# 3066H register map
File version: 1.0
Registers are 32-bit, access per field, reset 0x0 unless marked. A register's access mark holds for its fields unless they carry their own. Offsets are from the block's base; [hi:lo] are bit positions; {n}, {i} and the like mark numbered series; 'fields as' and 'values as' point back to an identical list.

## CRG — CRG peripheral interface
Base 0x10000000
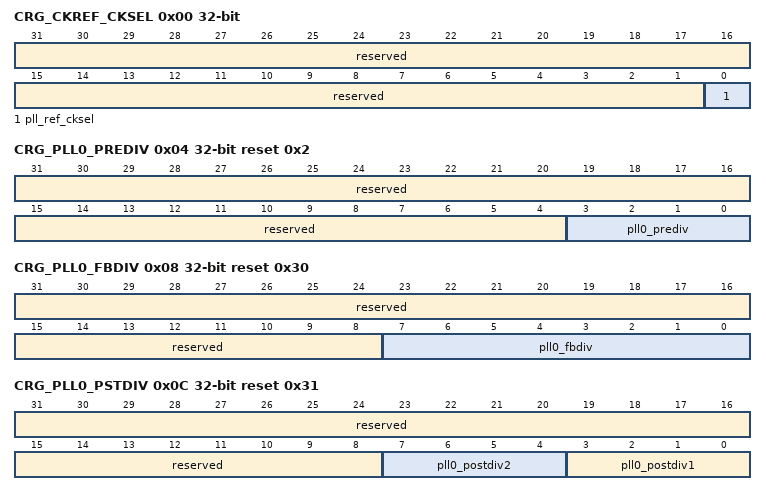
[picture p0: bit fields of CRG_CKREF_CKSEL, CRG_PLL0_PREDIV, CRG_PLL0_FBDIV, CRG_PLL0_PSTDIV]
0x00 CRG_CKREF_CKSEL access not given — CRG_CKREF_CKSEL为PLL参考钟选择寄存器。
  [31:1] reserved ro — 保留。
  [0] pll_ref_cksel — pll_ref_cksel信号。 0：选择HOSC； 1：选择晶振时钟。
0x04 CRG_PLL0_PREDIV access not given reset 0x2 — CRG_PLL0_PREDIV为自研PLL0寄存器0。
  [31:4] reserved ro — 保留。
  [3:0] pll0_prediv — pll0_prediv信号。 0x0：div1； 0x1：div2； 0x2：div3； 0x3：div4； 0x4：div5； 0x5：div6； 0x6：div7； 0x7：div8； 其他配置值：不使用。
0x08 CRG_PLL0_FBDIV access not given reset 0x30 — CRG_PLL0_FBDIV为自研PLL0寄存器1。
  [31:8] reserved ro — 保留。
  [7:0] pll0_fbdiv — pll0环路分频比。 0x00 ~ 0x06：div6； 0x07 ~ 0x7F：pll0_fbdiv； 其他配置值：不使用。 1MSB忽略。
0x0C CRG_PLL0_PSTDIV access not given reset 0x31 — CRG_PLL0_PSTDIV为自研PLL0寄存器2。
  [31:8] reserved ro — 保留。
  [7:4] pll0_postdiv2 — pll0_postdiv2信号。 0x0：÷1； 0x1：÷2； 0x2：÷3； 0x3：÷4； 0x4：÷5； 0x5：÷6； 0x6：÷7； 0x7：÷8； 其他配置值：不使用。
  [3:0] pll0_postdiv1 — pll0_postdiv1信号。 0x0：÷1； 0x1：÷2； 0x2：÷3； 0x3：÷4； 0x4：÷5； 0x5：÷6； 0x6：÷7； 0x7：÷8； 其他配置值：不使用。
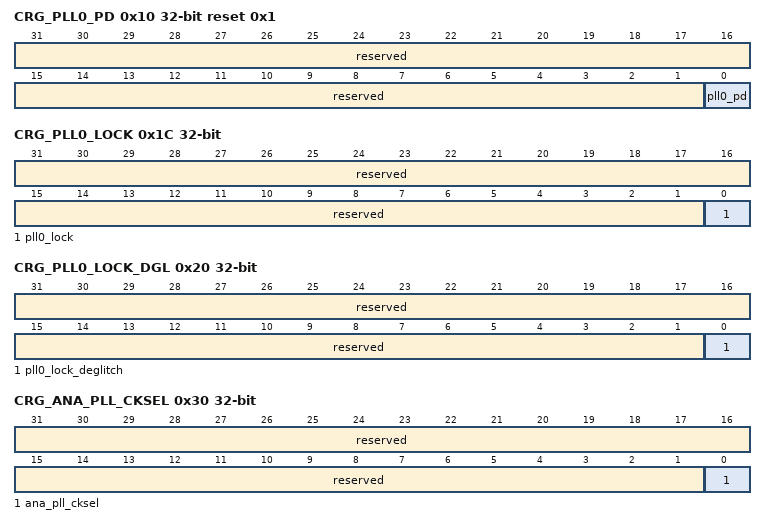
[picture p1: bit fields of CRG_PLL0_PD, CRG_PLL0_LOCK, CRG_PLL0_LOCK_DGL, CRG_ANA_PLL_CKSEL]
0x10 CRG_PLL0_PD access not given reset 0x1 — CRG_PLL0_PD为自研PLL0寄存器3。
  [31:1] reserved ro — 保留。
  [0] pll0_pd — pll0掉电使能（power down）。 0：pll0使能； 1：pll0掉电（power down）。
0x1C CRG_PLL0_LOCK ro — CRG_PLL0_LOCK为PLL0输出lock信息寄存器。
  [31:1] reserved — 保留。
  [0] pll0_lock — pll0 lock信号。 0：unlock； 1：lock。
0x20 CRG_PLL0_LOCK_DGL ro — CRG_PLL0_LOCK_DGL为PLL0输出lock去毛刺信号寄存器。
  [31:1] reserved — 保留。
  [0] pll0_lock_deglitch — pll0 lock硬件虑毛刺之后信号。 0：unlock； 1：lock。
0x30 CRG_ANA_PLL_CKSEL access not given — CRG_ANA_PLL_CKSEL为100MHz模拟时钟源选择寄存器。
  [31:1] reserved ro — 保留。
  [0] ana_pll_cksel — ana_pll_cksel信号。 0：FOUT_ANA（100MHz）时钟来自于PLL0； 1：FOUT_ANA（100MHz）时钟来自于PLL1。
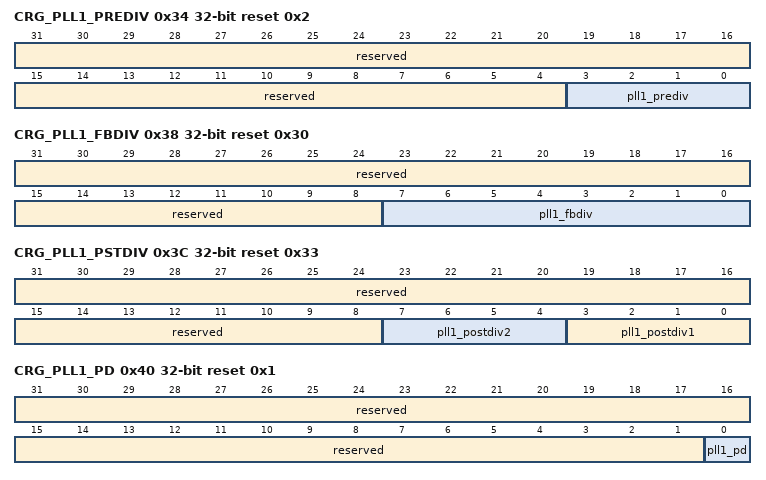
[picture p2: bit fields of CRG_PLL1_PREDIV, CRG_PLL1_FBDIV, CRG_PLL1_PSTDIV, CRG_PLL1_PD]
0x34 CRG_PLL1_PREDIV access not given reset 0x2 — CRG_PLL1_PREDIV为自研PLL1寄存器0。
  [31:4] reserved ro — 保留。
  [3:0] pll1_prediv — pll1_prediv信号。 0x0：div1； 0x1：div2； 0x2：div3； 0x3：div4； 0x4：div5； 0x5：div6； 0x6：div7； 0x7：div8； 其他配置值：不使用。
0x38 CRG_PLL1_FBDIV access not given reset 0x30 — CRG_PLL1_FBDIV为自研PLL1寄存器1。
  [31:8] reserved ro — 保留。
  [7:0] pll1_fbdiv — pll1环路分频比。 0x00~0x06：div6； 0x07~0x7F：pll1_FBDIV； 其他配置值：不使用。 1MSB忽略。
0x3C CRG_PLL1_PSTDIV access not given reset 0x33 — CRG_PLL1_PSTDIV为自研PLL1寄存器2。
  [31:8] reserved ro — 保留。
  [7:4] pll1_postdiv2 — pll1_postdiv2信号。 0x0：÷1； 0x1：÷2； 0x2：÷3； 0x3：÷4； 0x4：÷5； 0x5：÷6； 0x6：÷7； 0x7：÷8； 其他配置值：不使用。
  [3:0] pll1_postdiv1 — pll1_postdiv1信号。 0x0：÷1； 0x1：÷2； 0x2：÷3； 0x3：÷4； 0x4：÷5； 0x5：÷6； 0x6：÷7； 0x7：÷8； 其他配置值：不使用。
0x40 CRG_PLL1_PD access not given reset 0x1 — CRG_PLL1_PD为自研PLL1寄存器3。
  [31:1] reserved ro — 保留。
  [0] pll1_pd — pll1掉电使能（power down）。 0：pll1使能； 1：pll1掉电（power down）。
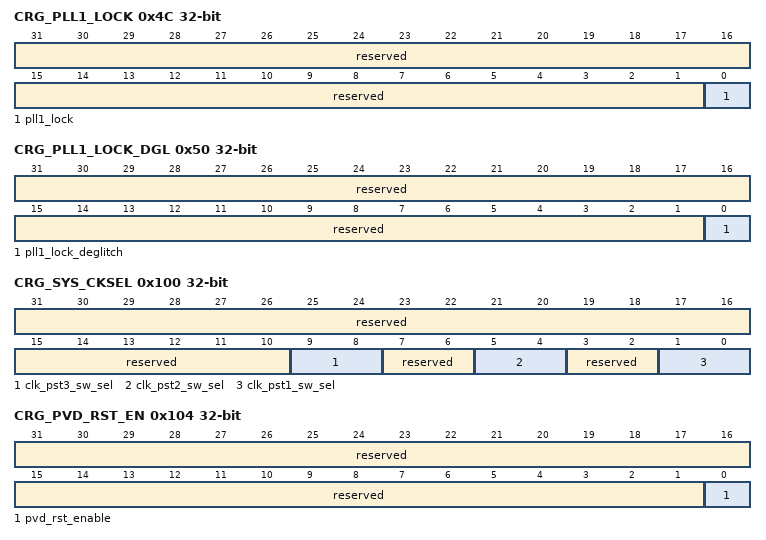
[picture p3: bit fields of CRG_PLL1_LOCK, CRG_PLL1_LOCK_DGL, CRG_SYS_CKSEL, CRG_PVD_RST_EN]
0x4C CRG_PLL1_LOCK ro — CRG_PLL1_LOCK为PLL1输出lock信息寄存器。
  [31:1] reserved — 保留。
  [0] pll1_lock — pll1 lock信号。 0：unlock； 1：lock。
0x50 CRG_PLL1_LOCK_DGL ro — CRG_PLL1_LOCK_DGL为PLL1输出lock去毛刺信号寄存器。
  [31:1] reserved — 保留。
  [0] pll1_lock_deglitch — pll1 lock硬件虑毛刺之后信号。 0：unlock； 1：lock。
0x100 CRG_SYS_CKSEL access not given — CRG_SYS_CKSEL为系统时钟控制寄存器。
  [31:10] reserved ro — 保留。
  [9:8] clk_pst3_sw_sel — clk_pst3_sw_sel信号。 00：选择HOSC； 01：选择晶振时钟； 10：选择PLL输出时钟； 其他：保留。
  [7:6] reserved ro — 保留。
  [5:4] clk_pst2_sw_sel — clk_pst2_sw_sel信号。 00：选择HOSC； 01：选择晶振时钟； 10：选择PLL输出时钟； 其他：保留。
  [3:2] reserved ro — 保留。
  [1:0] clk_pst1_sw_sel — hclk_sw_sel信号。 00：选择HOSC； 01：选择晶振时钟； 10：选择PLL输出时钟； 其他：保留。
0x104 CRG_PVD_RST_EN — CRG_PVD_RST_EN为PVD复位控制寄存器。
  [31:1] reserved ro — 保留。
  [0] pvd_rst_enable rw — pvd_rst使能寄存器。 0：不使能； 1：使能。
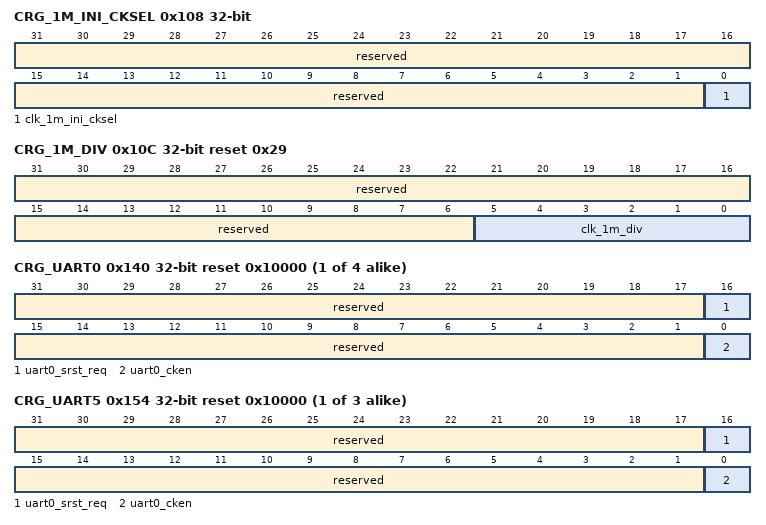
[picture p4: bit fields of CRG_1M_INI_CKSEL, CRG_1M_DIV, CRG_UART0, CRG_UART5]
0x108 CRG_1M_INI_CKSEL — CRG_1M_INI_CKSEL为CLK_1M时钟源头选择控制寄存器。
  [31:1] reserved ro — 保留。
  [0] clk_1m_ini_cksel rw — clk_1m_ini_cksel信号。 0：选择HOSC，default； 1：选择外部晶振时钟。 默认使用HOSC时钟。
0x10C CRG_1M_DIV reset 0x29 — CRG_1M_DIV为CLK_1M时钟分频控制寄存器。
  [31:6] reserved ro — 保留。
  [5:0] clk_1m_div rw — clk_1m分频参数。 输出时钟频率为输入时钟频率/（clk_1m_tick_div + 1）。 默认42分频，配0x29。
{0x140+4i} CRG_UART{i} reset 0x10000 (i=0..3) — CRG_UART{i}为UART{i}时钟及软复位控制寄存器。
  [31:17] reserved ro — 保留。
  [16] uart{i}_srst_req rw — UART{i}软复位请求。 0：不复位； 1：复位。
  [15:1] reserved ro — 保留。
  [0] uart{i}_cken rw — UART{i}时钟门控。 0：关断； 1：打开。
0x150 CRG_UART4 reset 0x10000 — CRG_UART4为UART4时钟及软复位控制寄存器。
  [16] uart4_srst_req rw — UART4软复位请求。 0：不复位； 1：复位。
  [31:14] reserved ro — 保留。
  [15:1] reserved ro — 保留。
  [0] uart4_cken rw — UART4时钟门控。 0：关断； 1：打开。
{0x140+4i} CRG_UART{i} reset 0x10000 (i=5..7) — CRG_UART{i}为UART{i}时钟及软复位控制寄存器。
  fields as CRG_UART0
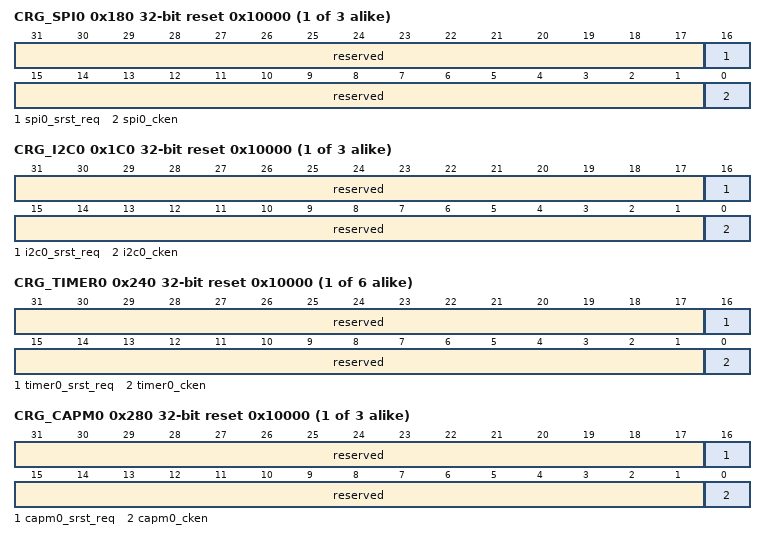
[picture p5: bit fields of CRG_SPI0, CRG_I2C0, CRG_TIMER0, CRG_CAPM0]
{0x180+4i} CRG_SPI{i} reset 0x10000 (i=0..2) — CRG_SPI{i}为SPI{i}时钟及软复位控制寄存器。
  [31:17] reserved ro — 保留。
  [16] spi{i}_srst_req rw — SPI{i}软复位请求。 0：不复位； 1：复位。
  [15:1] reserved ro — 保留。
  [0] spi{i}_cken rw — SPI{i}时钟门控。 0：关断； 1：打开。
{0x1C0+4i} CRG_I2C{i} reset 0x10000 (i=0..2) — CRG_I2C{i}为I2C时钟及软复位控制寄存器{i}。
  [31:17] reserved ro — 保留。
  [16] i2c{i}_srst_req rw — I2C{i}软复位请求。 0：不复位； 1：复位。
  [15:1] reserved ro — 保留。
  [0] i2c{i}_cken rw — I2C{i}时钟门控。 0：关断； 1：打开。
{0x240+4i} CRG_TIMER{i} reset 0x10000 (i=0..5) — CRG_TIMER{i}为Timer{i}时钟及软复位控制寄存器。
  [31:17] reserved ro — 保留。
  [16] timer{i}_srst_req rw — TIMER{i}软复位请求。 0：不复位； 1：复位。
  [15:1] reserved ro — 保留。
  [0] timer{i}_cken rw — TIMER{i}时钟门控。 0：关断； 1：打开。
{0x280+4i} CRG_CAPM{i} reset 0x10000 (i=0..2) — CRG_CAPM{i}为CAPM{i}时钟及软复位控制寄存器。
  [31:17] reserved ro — 保留。
  [16] capm{i}_srst_req rw — CAPM{i}软复位请求。 0：不复位； 1：复位。
  [15:1] reserved ro — 保留。
  [0] capm{i}_cken rw — CAPM{i}时钟门控。 0：关断； 1：打开。
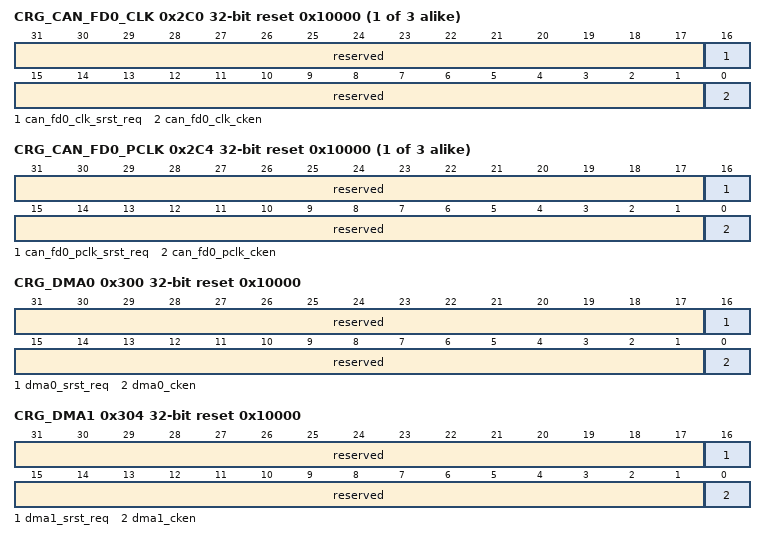
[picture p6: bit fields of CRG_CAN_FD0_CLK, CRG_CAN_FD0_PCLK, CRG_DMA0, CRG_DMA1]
{0x2C0+8i} CRG_CAN_FD{i}_CLK reset 0x10000 (i=0..2) — CRG_CAN_FD{i}_CLK为CAN_FD{i}工作时钟及软复位控制寄存器。
  [31:17] reserved ro — 保留。
  [16] can_fd{i}_clk_srst_req rw — clk_can_fd{i}软复位请求。 0：不复位； 1：复位。
  [15:1] reserved ro — 保留。
  [0] can_fd{i}_clk_cken rw — clk_can_fd{i}时钟门控。 0：关断； 1：打开。
{0x2C4+8i} CRG_CAN_FD{i}_PCLK reset 0x10000 (i=0..2) — CRG_CAN_FD{i}_PCLK为CAN_FD{i}总线时钟及软复位控制寄存器。
  [31:17] reserved ro — 保留。
  [16] can_fd{i}_pclk_srst_req rw — pclk_can_fd{i}软复位请求。 0：不复位； 1：复位。
  [15:1] reserved ro — 保留。
  [0] can_fd{i}_pclk_cken rw — pclk_can_fd{i}时钟门控。 0：关断； 1：打开。
0x300 CRG_DMA0 reset 0x10000 — CRG_DMA0为DMA0时钟及软复位控制寄存器。
  [31:17] reserved ro — 保留。
  [16] dma0_srst_req rw — DMA0软复位请求。 0：不复位； 1：复位。
  [15:1] reserved ro — 保留。
  [0] dma0_cken rw — DMA0时钟门控。 0：关断； 1：打开。
0x304 CRG_DMA1 reset 0x10000 — CRG_DMA1为DMA1时钟及软复位控制寄存器。
  [31:17] reserved ro — 保留。
  [16] dma1_srst_req rw — DMA1软复位请求。 0：不复位； 1：复位。
  [15:1] reserved ro — 保留。
  [0] dma1_cken rw — DMA1时钟门控。 0：关断； 1：打开。
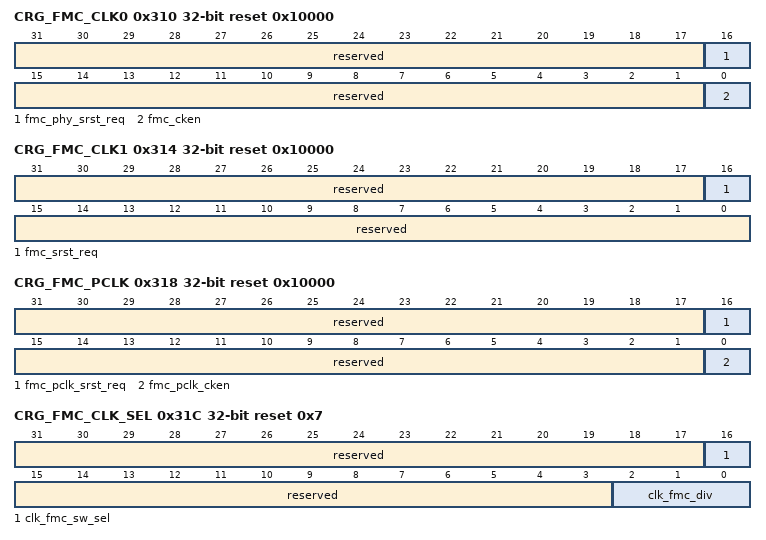
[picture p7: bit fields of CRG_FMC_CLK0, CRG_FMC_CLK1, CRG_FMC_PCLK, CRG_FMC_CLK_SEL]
0x310 CRG_FMC_CLK0 reset 0x10000 — CRG_FMC_CLK0为FMC时钟及软复位控制寄存器0。
  [31:17] reserved ro — 保留。
  [16] fmc_phy_srst_req rw — clk_fmc_phy软复位请求。 0：不复位； 1：复位。
  [15:1] reserved ro — 保留。
  [0] fmc_cken rw — clk_fmc时钟门控。 0：关断； 1：打开。
0x314 CRG_FMC_CLK1 reset 0x10000 — CRG_FMC_CLK1为FMC时钟及软复位控制寄存器1。
  [31:17] reserved ro — 保留。
  [16] fmc_srst_req rw — clk_fmc软复位请求。 0：不复位； 1：复位。
  [15:0] reserved ro — 保留。
0x318 CRG_FMC_PCLK reset 0x10000 — CRG_FMC_PCLK为FMC_PCLK时钟及软复位控制寄存器。
  [31:17] reserved ro — 保留。
  [16] fmc_pclk_srst_req rw — pclk_fmc软复位请求。 0：不复位； 1：复位。
  [15:1] reserved ro — 保留。
  [0] fmc_pclk_cken rw — pclk_fmc时钟门控。 0：关断； 1：打开。
0x31C CRG_FMC_CLK_SEL reset 0x7 — CRG_FMC_CLK_SEL为FMC_CLK_SEL时钟选择控制寄存器。
  [31:17] reserved ro — 保留。
  [16] clk_fmc_sw_sel rw — clk_fmc_sw_sel信号。 0：选择VCO时钟（clk_fmc_div + 1）分频； 1：选择HOSC时钟。
  [15:3] reserved ro — 保留。
  [2:0] clk_fmc_div rw — fmc_phy时钟分频参数。 输出时钟频率为输入时钟频率/（clk_fmc_div + 1）。 不分频，配0。
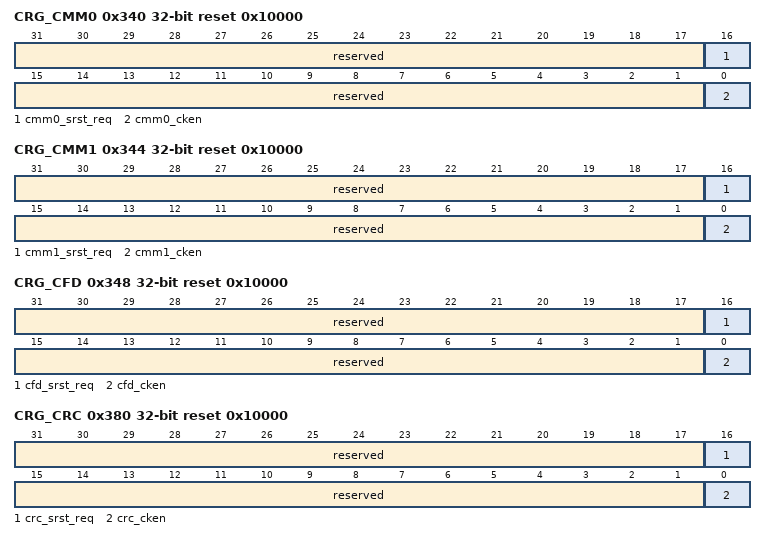
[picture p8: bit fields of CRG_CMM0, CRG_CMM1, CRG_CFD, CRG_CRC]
0x340 CRG_CMM0 reset 0x10000 — CRG_CMM0为CMM0时钟及软复位控制寄存器。
  [31:17] reserved ro — 保留。
  [16] cmm0_srst_req rw — CMM0软复位请求。 0：不复位； 1：复位。
  [15:1] reserved ro — 保留。
  [0] cmm0_cken rw — CMM0时钟门控。 0：关断； 1：打开。
0x344 CRG_CMM1 reset 0x10000 — CRG_CMM1为CMM1时钟及软复位控制寄存器。
  [31:17] reserved ro — 保留。
  [16] cmm1_srst_req rw — CMM1软复位请求。 0：不复位； 1：复位。
  [15:1] reserved ro — 保留。
  [0] cmm1_cken rw — CMM1时钟门控。 0：关断； 1：打开。
0x348 CRG_CFD reset 0x10000 — CRG_CFD为CFD时钟及软复位控制寄存器。
  [31:17] reserved ro — 保留。
  [16] cfd_srst_req rw — CFD软复位请求。 0：不复位； 1：复位。
  [15:1] reserved ro — 保留。
  [0] cfd_cken rw — CFD时钟门控。 0：关断； 1：打开。
0x380 CRG_CRC reset 0x10000 — CRG_CRC为CRC时钟及软复位控制寄存器。
  [31:17] reserved ro — 保留。
  [16] crc_srst_req rw — CRC软复位请求。 0：不复位； 1：复位。
  [15:1] reserved ro — 保留。
  [0] crc_cken rw — CRC时钟门控。 0：关断； 1：打开。
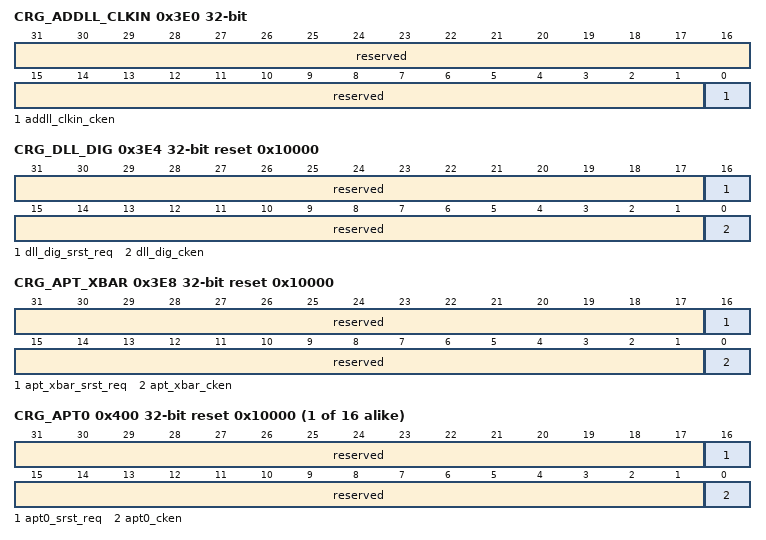
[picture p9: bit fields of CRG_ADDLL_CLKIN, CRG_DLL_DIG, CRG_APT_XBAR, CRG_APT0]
0x3E0 CRG_ADDLL_CLKIN — CRG_ADDLL_CLKIN为ADDLL_CLKIN时钟及软复位控制寄存器。
  [31:1] reserved ro — 保留。
  [0] addll_clkin_cken rw — addll_clkin时钟门控。 0：关断； 1：打开。
0x3E4 CRG_DLL_DIG reset 0x10000 — CRG_DLL_DIG为DLL_DIG时钟及软复位控制寄存器。
  [31:17] reserved ro — 保留。
  [16] dll_dig_srst_req rw — dll_dig软复位请求。 0：不复位； 1：复位。
  [15:1] reserved ro — 保留。
  [0] dll_dig_cken rw — dll_dig时钟门控。 0：关断； 1：打开。
0x3E8 CRG_APT_XBAR reset 0x10000 — CRG_APT_XBAR为APT_XBAR时钟及软复位控制寄存器。
  [31:17] reserved ro — 保留。
  [16] apt_xbar_srst_req rw — apt_xbar软复位请求。 0：不复位； 1：复位。
  [15:1] reserved ro — 保留。
  [0] apt_xbar_cken rw — apt_xbar时钟门控。 0：关断； 1：打开。
{0x400+4i} CRG_APT{i} reset 0x10000 (i=0..15) — CRG_APT{i}为APT{i}时钟及软复位控制寄存器。
  [31:17] reserved ro — 保留。
  [16] apt{i}_srst_req rw — APT{i}软复位请求。 0：不复位； 1：复位。
  [15:1] reserved ro — 保留。
  [0] apt{i}_cken rw — APT{i}时钟门控。 0：关断； 1：打开。
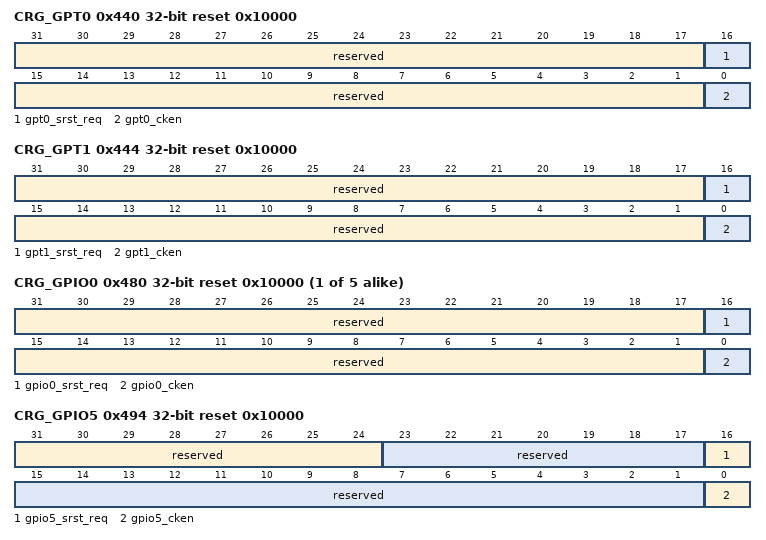
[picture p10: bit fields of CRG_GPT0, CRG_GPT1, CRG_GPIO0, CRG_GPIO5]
0x440 CRG_GPT0 reset 0x10000 — CRG_GPT0为GPT0时钟及软复位控制寄存器。
  [31:17] reserved ro — 保留。
  [16] gpt0_srst_req rw — GPT0软复位请求。 0：不复位； 1：复位。
  [15:1] reserved ro — 保留。
  [0] gpt0_cken rw — GPT0时钟门控。 0：关断； 1：打开。
0x444 CRG_GPT1 reset 0x10000 — CRG_GPT1为GPT1时钟及软复位控制寄存器。
  [31:17] reserved ro — 保留。
  [16] gpt1_srst_req rw — GPT1软复位请求。 0：不复位； 1：复位。
  [15:1] reserved ro — 保留。
  [0] gpt1_cken rw — GPT1时钟门控。 0：关断； 1：打开。
{0x480+4i} CRG_GPIO{i} reset 0x10000 (i=0..4) — CRG_GPIO{i}为GPIO{i}时钟及软复位控制寄存器。
  [31:17] reserved ro — 保留。
  [16] gpio{i}_srst_req rw — GPIO{i}软复位请求。 0：不复位； 1：复位。
  [15:1] reserved ro — 保留。
  [0] gpio{i}_cken rw — GPIO{i}时钟门控。 0：关断； 1：打开。
0x494 CRG_GPIO5 reset 0x10000 — CRG_GPIO5为GPIO5时钟及软复位控制寄存器。
  [31:24] reserved ro — 保留。
  [23:17] reserved ro — 保留。
  [16] gpio5_srst_req rw — GPIO5软复位请求。 0：不复位； 1：复位。
  [15:1] reserved ro — 保留。
  [0] gpio5_cken rw — GPIO5时钟门控。 0：关断； 1：打开。
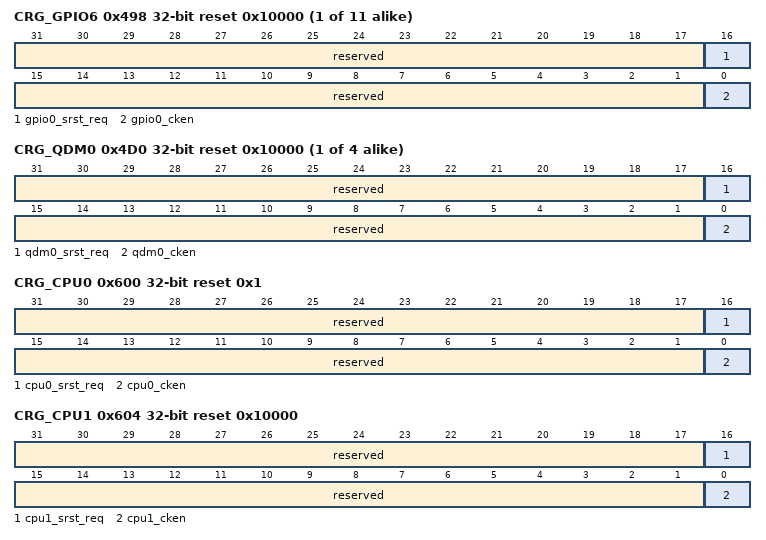
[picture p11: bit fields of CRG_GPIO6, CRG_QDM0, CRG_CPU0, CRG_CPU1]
{0x480+4i} CRG_GPIO{i} reset 0x10000 (i=6..16) — CRG_GPIO{i}为GPIO{i}时钟及软复位控制寄存器。
  fields as CRG_GPIO0
{0x4D0+4i} CRG_QDM{i} reset 0x10000 (i=0..3) — CRG_QDM{i}为QDM{i}时钟及软复位控制寄存器。
  [31:17] reserved ro — 保留。
  [16] qdm{i}_srst_req rw — QDM{i}软复位请求。 0：不复位； 1：复位。
  [15:1] reserved ro — 保留。
  [0] qdm{i}_cken rw — QDM{i}时钟门控。 0：关断； 1：打开。
0x600 CRG_CPU0 reset 0x1 — CRG_CPU0为CPU0时钟及软复位控制寄存器。
  [31:17] reserved ro — 保留。
  [16] cpu0_srst_req rw — CPU0软复位请求。 0：不复位； 1：复位。
  [15:1] reserved ro — 保留。
  [0] cpu0_cken rw — CPU0时钟门控。 0：关断； 1：打开。
0x604 CRG_CPU1 reset 0x10000 — CRG_CPU1为CPU1时钟及软复位控制寄存器。
  [31:17] reserved ro — 保留。
  [16] cpu1_srst_req rw — CPU1软复位请求。 0：不复位； 1：复位。
  [15:1] reserved ro — 保留。
  [0] cpu1_cken rw — CPU1时钟门控。 0：关断； 1：打开。
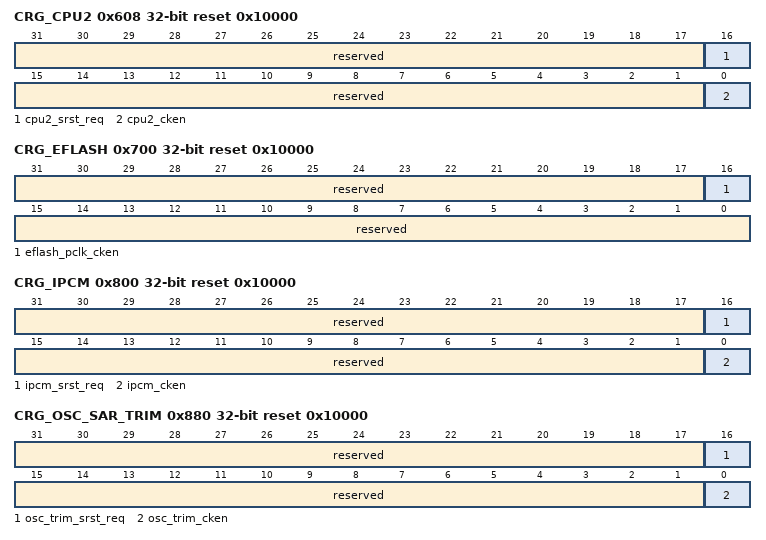
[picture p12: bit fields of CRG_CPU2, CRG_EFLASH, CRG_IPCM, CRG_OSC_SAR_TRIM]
0x608 CRG_CPU2 reset 0x10000 — CRG_CPU2为CPU2时钟及软复位控制寄存器。
  [31:17] reserved ro — 保留。
  [16] cpu2_srst_req rw — CPU2软复位请求。 0：不复位； 1：复位。
  [15:1] reserved ro — 保留。
  [0] cpu2_cken rw — CPU2时钟门控。 0：关断； 1：打开。
0x700 CRG_EFLASH access not given reset 0x10000 — CRG_EFLASH为eFLASH时钟控制寄存器。
  [31:17] reserved ro — 保留。
  [16] eflash_pclk_cken — eflash_pclk_cken时钟门控。 0：关断； 1：打开。
  [15:0] reserved ro — 保留。
0x800 CRG_IPCM reset 0x10000 — CRG_IPCM为IPCM时钟及软复位控制寄存器。
  [31:17] reserved ro — 保留。
  [16] ipcm_srst_req rw — IPCM软复位请求。 0：不复位； 1：复位。
  [15:1] reserved ro — 保留。
  [0] ipcm_cken rw — IPCM时钟门控。 0：关断； 1：打开。
0x880 CRG_OSC_SAR_TRIM reset 0x10000 — CRG_OSC_SAR_TRIM为OSC_SAR_TRIM时钟及软复位控制寄存器。
  [31:17] reserved ro — 保留。
  [16] osc_trim_srst_req rw — osc_trim软复位请求。 0：不复位； 1：复位。
  [15:1] reserved ro — 保留。
  [0] osc_trim_cken rw — osc_trim时钟门控。 0：关断； 1：打开。
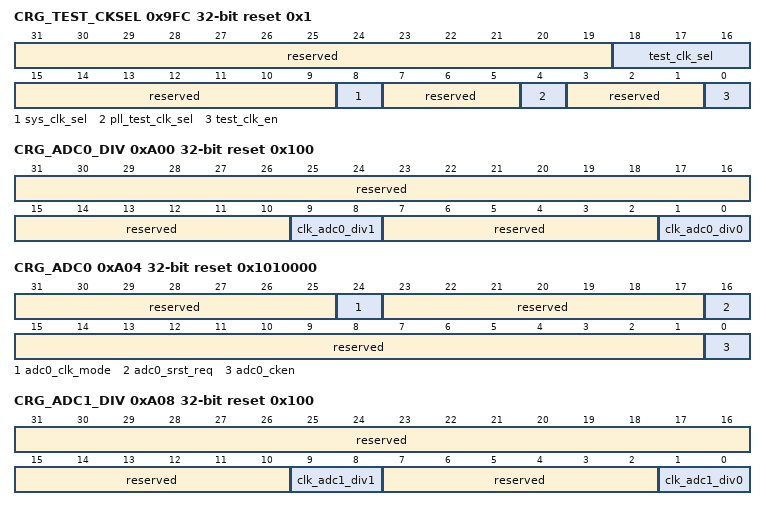
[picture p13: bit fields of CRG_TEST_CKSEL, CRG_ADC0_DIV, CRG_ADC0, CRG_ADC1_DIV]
0x9FC CRG_TEST_CKSEL reset 0x1 — CRG_TEST_CKSEL为TEST时钟选择控制寄存器。
  [31:19] reserved ro — 保留。
  [18:16] test_clk_sel rw — TEST_CLK时钟选择。 000：pll_test时钟； 001：clk_hosc； 010：clk_losc； 011：clk_tcxo； 100：clk_bg_chopper； 101：clk_adc/4； 110：sys_clk/6； 111：clk_hosc_div。
  [15:9] reserved ro — 保留。
  [8] sys_clk_sel rw — sys_clk时钟选择。 0：clk_hs时钟； 1：clk_ls时钟。
  [7:5] reserved ro — 保留。
  [4] pll_test_clk_sel rw — pll_test时钟选择。 0：pll0_test时钟； 1：pll1_test时钟。
  [3:1] reserved ro — 保留。
  [0] test_clk_en rw — test_clk_en。 0：不使能； 1：使能。
0xA00 CRG_ADC0_DIV reset 0x100 — CRG_ADC0_DIV为ADC0分频时钟配置寄存器。
  [31:10] reserved ro — 保留。
  [9:8] clk_adc0_div1 rw — clk_adc0 I1路时钟分频参数 输出时钟频率为输入时钟频率/（clk_adc_div + 1）。 默认二分频，配1。
  [7:2] reserved ro — 保留。
  [1:0] clk_adc0_div0 rw — clk_adc0 I0路时钟分频参数 输出时钟频率为输入时钟频率/（clk_adc_div + 1）。 默认不分频，配0。
0xA04 CRG_ADC0 reset 0x1010000 — CRG_ADC0为ADC0时钟及软复位控制寄存器
  [31:25] reserved ro — 保留。
  [24] adc0_clk_mode rw — clk_adc0选择信号。 0：选择I0路，PLL FOUTPOSTDIV2出来100M时钟，default； 1：选择I1路，主频时钟经过分频后的时钟。
  [23:17] reserved ro — 保留。
  [16] adc0_srst_req rw — ADC0软复位请求。 0：不复位； 1：复位。
  [15:1] reserved ro — 保留。
  [0] adc0_cken rw — ADC0时钟门控。 0：关断； 1：打开。
0xA08 CRG_ADC1_DIV reset 0x100 — CRG_ADC1_DIV为ADC1分频时钟配置寄存器
  [31:10] reserved ro — 保留。
  [9:8] clk_adc1_div1 rw — clk_adc1 I1路时钟分频参数。 输出时钟频率为输入时钟频率/（clk_adc_div + 1）。 默认二分频，配1。
  [7:2] reserved ro — 保留。
  [1:0] clk_adc1_div0 rw — clk_adc1 I0路时钟分频参数。 输出时钟频率为输入时钟频率/（clk_adc_div + 1）。 默认不分频，配0。
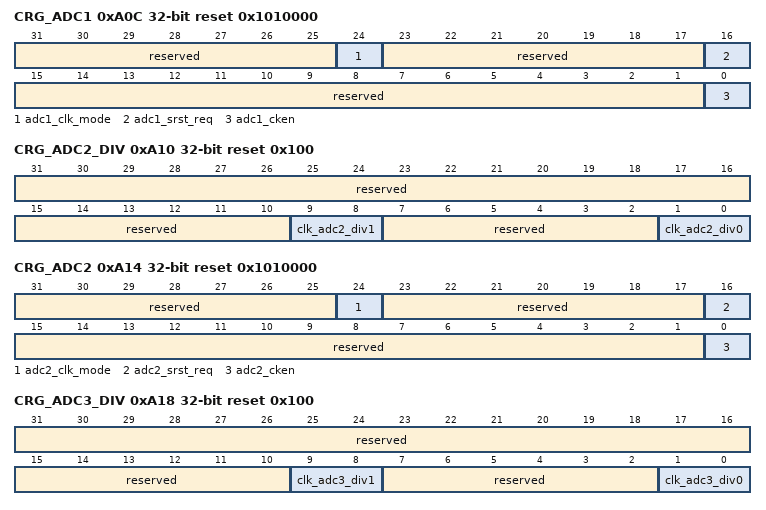
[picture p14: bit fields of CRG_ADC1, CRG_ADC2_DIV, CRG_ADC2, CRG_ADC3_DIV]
0xA0C CRG_ADC1 reset 0x1010000 — CRG_ADC1为ADC1时钟及软复位控制寄存器
  [31:25] reserved ro — 保留。
  [24] adc1_clk_mode rw — clk_adc1选择信号。 0：选择I0路，PLL FOUTPOSTDIV2出来100M时钟，default； 1：选择I1路，主频时钟经过分频后的时钟。
  [23:17] reserved ro — 保留。
  [16] adc1_srst_req rw — ADC1软复位请求。 0：不复位； 1：复位。
  [15:1] reserved ro — 保留。
  [0] adc1_cken rw — ADC1时钟门控。 0：关断； 1：打开。
0xA10 CRG_ADC2_DIV reset 0x100 — CRG_ADC2_DIV为ADC2分频时钟配置寄存器
  [31:10] reserved ro — 保留。
  [9:8] clk_adc2_div1 rw — clk_adc2 I1路时钟分频参数。 输出时钟频率为输入时钟频率/（clk_adc_div + 1）。 默认二分频，配1。
  [7:2] reserved ro — 保留。
  [1:0] clk_adc2_div0 rw — clk_adc2 I0路时钟分频参数。 输出时钟频率为输入时钟频率/（clk_adc_div + 1）。 默认不分频，配0。
0xA14 CRG_ADC2 reset 0x1010000 — CRG_ADC2为ADC2时钟及软复位控制寄存器。
  [31:25] reserved ro — 保留。
  [24] adc2_clk_mode rw — clk_adc2选择信号。 0：选择I0路，PLL FOUTPOSTDIV2出来100M时钟，default； 1：选择I1路，主频时钟经过分频后的时钟。
  [23:17] reserved ro — 保留。
  [16] adc2_srst_req rw — ADC2软复位请求。 0：不复位； 1：复位。
  [15:1] reserved ro — 保留。
  [0] adc2_cken rw — ADC2时钟门控。 0：关断； 1：打开。
0xA18 CRG_ADC3_DIV reset 0x100 — CRG_ADC3_DIV为ADC3分频时钟配置寄存器。
  [31:10] reserved ro — 保留。
  [9:8] clk_adc3_div1 rw — clk_adc3 I1路时钟分频参数。 输出时钟频率为输入时钟频率/（clk_adc_div + 1）。 默认二分频，配1。
  [7:2] reserved ro — 保留。
  [1:0] clk_adc3_div0 rw — clk_adc3 I0路时钟分频参数。 输出时钟频率为输入时钟频率/（clk_adc_div + 1）。 默认不分频，配0。
0xA1C CRG_ADC3 reset 0x1010000 — CRG_ADC3为ADC3时钟及软复位控制寄存器。
  [31:25] reserved ro — 保留。
  [24] adc3_clk_mode rw — clk_adc3选择信号。 0：选择I0路，PLL FOUTPOSTDIV2出来100M时钟，default； 1：选择I1路，主频时钟经过分频后的时钟。
  [23:17] reserved ro — 保留。
  [16] adc3_srst_req rw — ADC3软复位请求。 0：不复位； 1：复位。
  [15:1] reserved ro — 保留。
  [0] adc3_cken rw — ADC3时钟门控。 0：关断； 1：打开。
0xA20 CRG_ADC0_CLK_PCTL — CRG_ADC0_CLK_PCTL为ADC0时钟反相控制寄存器。
  [31:1] reserved ro — 保留。
  [0] adc0_clk_pctl rw — ADC0时钟反相控制。 0：不反向； 1：反向。
0xA24 CRG_ADC1_CLK_PCTL reset 0x1 — CRG_ADC1_CLK_PCTL为ADC1时钟反相控制寄存器。
  [31:1] reserved ro — 保留。
  [0] adc1_clk_pctl rw — ADC1时钟反相控制。 0：不反向； 1：反向。
0xA28 CRG_ADC2_CLK_PCTL — CRG_ADC2_CLK_PCTL为ADC2时钟反相控制寄存器。
  [31:1] reserved ro — 保留。
  [0] adc2_clk_pctl rw — ADC2时钟反相控制。 0：不反向； 1：反向。
0xA2C CRG_ADC3_CLK_PCTL reset 0x1 — CRG_ADC3_CLK_PCTL为ADC3时钟反相控制寄存器。
  [31:1] reserved ro — 保留。
  [0] adc3_clk_pctl rw — ADC3时钟反相控制。 0：不反向； 1：反向。
0xA50 CRG_ANA reset 0x10000 — CRG_ANA为CLK_ANA时钟控制寄存器。
  [31:17] reserved ro — 保留。
  [16] ana_srst_req rw — prst_ana_n软复位请求。 0：不复位； 1：复位。
  [15:1] reserved ro — 保留。
  [0] clk_ana_cken rw — clk_ana时钟门控。 0：关断； 1：打开。
0xA60 CRG_VREF reset 0x10000 — CRG_VREF为VREF软复位请求寄存器。
  [31:17] reserved ro — 保留。
  [16] vref_srst_req rw — prst_vref_n软复位请求。 0：不复位； 1：复位。
  [15:0] reserved ro — 时钟门控保留。
{0xA70+4i} CRG_ACMP{i} reset 0x10000 (i=0..7) — CRG_ACMP{i}为ACMP{i}软复位请求寄存器。
  [31:17] reserved ro — 保留。
  [16] acmp{i}_srst_req rw — prst_acmp{i}_n软复位请求。 0：不复位； 1：复位。
  [15:0] reserved ro — 时钟门控保留。
{0xA90+4i} CRG_DAC{i} reset 0x10000 (i=0..7) — CRG_DAC{i}为DAC{i}软复位请求寄存器。
  [31:17] reserved ro — 保留。
  [16] dac{i}_srst_req rw — prst_dac{i}_n软复位请求。 0：不复位； 1：复位。
  [15:0] reserved ro — 时钟门控保留。
0xAB0 CRG_DAC8 reset 0x10000 — CRG_DAC8为DAC8（即DACBUFF）软复位请求寄存器。
  [31:17] reserved ro — 保留。
  [16] dac8_srst_req rw — prst_dac8_n软复位请求。 0：不复位； 1：复位。
  [15:0] reserved ro — 时钟门控保留。
{0xAB4+4i} CRG_PGA{i} reset 0x10000 (i=0..3) — CRG_PGA{i}为PGA{i}软复位请求寄存器。
  [31:17] reserved ro — 保留。
  [16] pga{i}_srst_req rw — prst_pga{i}_n软复位请求。 0：不复位； 1：复位。
  [15:0] reserved ro — 时钟门控保留。
0xB00 CRG_HPM reset 0x11 — CRG_HPM为hpm时钟及软复位控制寄存器。
  [31:21] reserved ro — 保留。
  [20] hpm_1m_srst_req rw — hpm_1m软复位请求。 0：不复位； 1：复位。
  [19:17] reserved ro — 保留。
  [16] hpm_srst_req rw — hpm软复位请求。 0：不复位； 1：复位。
  [15:5] reserved ro — 保留。
  [4] hpm_1m_cken rw — hpm_1m时钟门控。 0：关断； 1：打开。
  [3:1] reserved ro — 保留。
  [0] hpm_cken rw — hpm时钟门控。 0：关断； 1：打开。
0xEFC CRG_DEBUG ro — CRG_DEBUG为DEBUG寄存器。
  [31:10] reserved — 保留。
  [9:8] clk_pst3_sw_mux_sel — clk_pst3_sw_mux_sel信号。
  [7:6] reserved — 保留。
  [5:4] clk_pst2_sw_mux_sel — clk_pst2_sw_mux_sel信号。
  [3:2] reserved — 保留。
  [1:0] clk_pst1_sw_mux_sel — hclk_sw_mux_sel信号。
0xF00 HOSC_CTRL1 reset 0x19C — HOSC_CTRL1为HOSC配置寄存器0。
  [31:10] reserved ro — 保留。
  [9:0] hosc_ctrim_value rw — OSC25M Efuse频率调整控制值。 bit[9:1]：512 steps calib Cdac= 1.542p+ 7.46f*ctrim[9:1]。 bit[0]：2 steps calib Cdac= 3.725f*ctrim[0]。
0xF04 HOSC_CTRL2 reset 0x306E — HOSC_CTRL2为HOSC配置寄存器1。
  [31:24] reserved ro — 保留。
  [23:20] hosc_lpfr_sel rw — HOSC控制寄存器。 bit[3:2]：保留。 bit[1]：VREF RC短路控制信号。 0：RC short； 1：RC not short。 bit[0]：FS ENB信号。 0：FS使能； 1：FS不使能。
  [19:18] reserved ro — 保留。
  [17:16] hosc_kvco_sel rw — KVCO比例选择信号。 00：9:1； 01：6:1； 10：6:1； 11：4.5:1。
  [15] reserved ro — 保留。
  [14:12] hosc_sel_vref rw — OSC vref档位控制寄存器。 000：19.60M； 001：21M； 010：22.76M； 011：25M（default）0.9V； 100：28.06M； 101：32.15M； 110：38.26M； 111：48.34M。
  [11:8] hosc_itrim_value rw — 保留。
  [7:0] hosc_rtrim_value rw — OSC温漂系数控制信号寄存器。 bit[7]：保留。 bit[6:0]：OSC温度系数控制信号。 0x6E：+0.63%； 0x1E：+0.54%； 0x79‬：+0.49%；‬‬‬ 0x75：-0.38%； 0x6D：-0.47%； 0x3D：-0.55%； 0x73：-0.61%； 其他：保留。
0xF08 HOSC_CTRL3 reset 0x20000000 — HOSC_CTRL3为HOSC配置寄存器2。
  [31:30] reserved ro — 保留。
  [29:28] hosc_vsel_ldo_ref rw — LDO档位控制信号寄存器。 00：1.8V； 01：1.86V； 10：1.9V； 11：1.98V。
  [27:25] reserved ro — 保留。
  [24] hosc_start_up rw — 启动信号寄存器。 0：正常启动； 1：强制拉高vctrl。 reset vctrl in OSC analog phy Reserved。
  [23:18] reserved ro — 保留。
  [17:16] hosc_div_sel rw — CLK_DIV_OUT分频档位控制信号寄存器。 00：1024； 01：2048； 10：512； 11：256。
  [15:14] reserved ro — 保留。
  [13:4] hosc_test rw — HOSC测试寄存器。 bit[9]：select IBIAS bypass signal。 0：use normal mode； 1：use bypass mode。 bit[8]：select LDO bypass signal。 0：use normal mode； 1：use bypass mode。 bit[7]：保留。 bit[6]：select ad_test_dig signal。 0：use CLK_DIV_OUT； 1：use CLK_OUT。 bit[5:3]：select test_analog signal。 000：保留； 001：test avdd18； 010：test vctrl； 011：test vring； 100：test vref； 101：test lock； 110：test reset18； 111：test fs_ctl18。 bit[2]：Voltage divider control signal。 0：test voltage halved； 1：test voltage not divided。 bit[1]：select test voltage output mode。 0：direct output； 1：OP buffer。 bit[0]：analog test control signal。 0：analog test disable； 1：analog test enable。
  [3:2] reserved ro — 保留。
  [1] hosc_dft_en rw — DFT mode标志信号寄存器。 0：when REG_ATE_EN=0，CLK_OUT_ANALOG=CLK_OSC； When REG_ATE_EN=1，CLK_OUT_ANALOG=CLK_XTAL； 1：CLK_OUT_ANALOG=CLK_OSC。
  [0] hosc_ate_en rw — ATE mode切换寄存器。 0：not in ATE mode； 1：in ATE mode。
0xF0C HOSC_PD access not given — HOSC_PD为HOSC配置寄存器3。
  [31:1] reserved ro — 保留。
  [0] hosc_pd — HOSC power down。 0：HOSC enable； 1：HOSC power down。
0xF10 HOSC_LOCK ro — HOSC_LOCK为HOSC LOCK信号观测寄存器。
  [31:1] reserved — 保留。
  [0] hosc_lock — hosc_lock信号。
